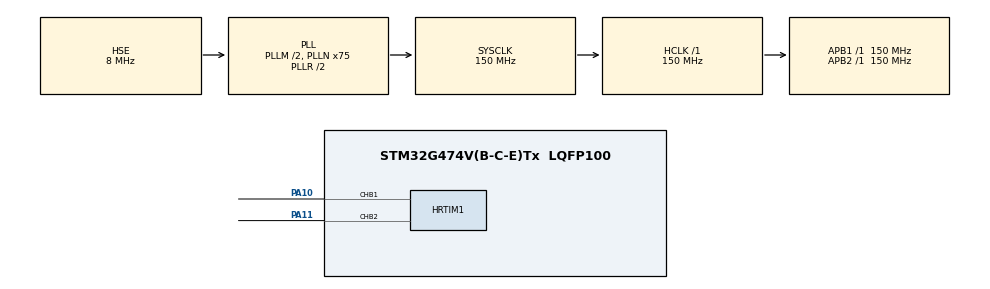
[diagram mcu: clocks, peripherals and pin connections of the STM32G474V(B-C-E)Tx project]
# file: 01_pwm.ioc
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HRTIM1.CompareUnit1-Output_TB1TB2=HRTIM_COMPAREUNIT_1
HRTIM1.CompareValue1-Output_TB1TB2=0
HRTIM1.DeadTimeInsertion-Output_TB1TB2=HRTIM_TIMDEADTIMEINSERTION_ENABLED
HRTIM1.FallingValue-Output_TB1TB2=200
HRTIM1.NumberResetSource1-Output_TB1TB2=1
HRTIM1.NumberSetSource1-Output_TB1TB2=1
HRTIM1.Periode_TB=30000
HRTIM1.PreloadEnable-Output_TB1TB2=HRTIM_PRELOAD_ENABLED
HRTIM1.PrescalerDead-Output_TB1TB2=HRTIM_TIMDEADTIME_PRESCALERRATIO_DIV1
HRTIM1.PrescalerRatio_TB=HRTIM_PRESCALERRATIO_MUL4
HRTIM1.RepetitionUpdate-Output_TB1TB2=HRTIM_UPDATEONREPETITION_ENABLED
HRTIM1.ResetOutput1_Source1-Output_TB1TB2=HRTIM_OUTPUTRESET_TIMCMP1
HRTIM1.RisingValue-Output_TB1TB2=200
HRTIM1.SetOutput1_Source1-Output_TB1TB2=HRTIM_OUTPUTSET_TIMPER
Mcu.Family=STM32G4
Mcu.Name=STM32G474V(B-C-E)Tx
Mcu.Package=LQFP100
NVIC.PriorityGroup=NVIC_PRIORITYGROUP_4
PA10.Mode=Output_TB1TB2
PA10.Signal=HRTIM1_CHB1
PA11.Mode=Output_TB1TB2
PA11.Signal=HRTIM1_CHB2
PA13.Mode=Serial_Wire
PA13.Signal=SYS_JTMS-SWDIO
PA14.Mode=Serial_Wire
PA14.Signal=SYS_JTCK-SWCLK
PC14-OSC32_IN.Mode=LSE-External-Oscillator
PC14-OSC32_IN.Signal=RCC_OSC32_IN
PC15-OSC32_OUT.Mode=LSE-External-Oscillator
PC15-OSC32_OUT.Signal=RCC_OSC32_OUT
PF0-OSC_IN.Mode=HSE-External-Oscillator
PF0-OSC_IN.Signal=RCC_OSC_IN
PF1-OSC_OUT.Mode=HSE-External-Oscillator
PF1-OSC_OUT.Signal=RCC_OSC_OUT
ProjectManager.HeapSize=0x200
ProjectManager.StackSize=0x400
ProjectManager.TargetToolchain=MDK-ARM V5.32
RCC.ADC12Freq_Value=150000000
RCC.ADC345Freq_Value=150000000
RCC.AHBFreq_Value=150000000
RCC.APB1Freq_Value=150000000
RCC.APB1TimFreq_Value=150000000
RCC.APB2Freq_Value=150000000
RCC.APB2TimFreq_Value=150000000
RCC.CortexFreq_Value=150000000
RCC.EXTERNAL_CLOCK_VALUE=12288000
RCC.HCLKFreq_Value=150000000
RCC.HSE_VALUE=8000000
RCC.HSI48_VALUE=48000000
RCC.HSI_VALUE=16000000
RCC.PLLM=RCC_PLLM_DIV2
RCC.PLLN=75
RCC.PLLSourceVirtual=RCC_PLLSOURCE_HSE
RCC.SYSCLKFreq_VALUE=150000000
RCC.SYSCLKSource=RCC_SYSCLKSOURCE_PLLCLK
RCC.USBFreq_Value=150000000
RCC.VCOOutputFreq_Value=300000000
VP_SYS_VS_DBSignals.Mode=DisableDeadBatterySignals
board=custom

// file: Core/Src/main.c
/* USER CODE BEGIN Header */
/**
  ******************************************************************************
  * @file           : main.c
  * @brief          : Main program body
  ******************************************************************************
  * @attention
  *
  * Copyright (c) 2026 STMicroelectronics.
  * All rights reserved.
  *
  * This software is licensed under terms that can be found in the LICENSE file
  * in the root directory of this software component.
  * If no LICENSE file comes with this software, it is provided AS-IS.
  *
  ******************************************************************************
  */
/* USER CODE END Header */
#include "main.h"
#include "hrtim.h"
#include "gpio.h"

void SystemClock_Config(void);

int main(void)
{

  /* MCU Configuration--------------------------------------------------------*/

  /* Reset of all peripherals, Initializes the Flash interface and the Systick. */
  HAL_Init();

  /* Configure the system clock */
  SystemClock_Config();

  /* Initialize all configured peripherals */
  MX_GPIO_Init();
  MX_HRTIM1_Init();

  /* Infinite loop */
  /* USER CODE BEGIN WHILE */

	HAL_HRTIM_WaveformCounterStart(&hhrtim1,HRTIM_TIMERID_TIMER_B);//开定时器
	HAL_HRTIM_WaveformOutputStart(&hhrtim1,HRTIM_OUTPUT_TB1|HRTIM_OUTPUT_TB2);//开通道
	HRTIM1->sTimerxRegs[HRTIM_TIMERINDEX_TIMER_B].CMP1CxR = 15000;//改占空比
  while (1)
  {
    /* USER CODE END WHILE */

  }
}

void SystemClock_Config(void)
{
  RCC_OscInitTypeDef RCC_OscInitStruct = {0};
  RCC_ClkInitTypeDef RCC_ClkInitStruct = {0};

  /** Configure the main internal regulator output voltage
  */
  HAL_PWREx_ControlVoltageScaling(PWR_REGULATOR_VOLTAGE_SCALE1);

  /** Initializes the RCC Oscillators according to the specified parameters
  * in the RCC_OscInitTypeDef structure.
  */
  RCC_OscInitStruct.OscillatorType = RCC_OSCILLATORTYPE_HSE;
  RCC_OscInitStruct.HSEState = RCC_HSE_ON;
  RCC_OscInitStruct.PLL.PLLState = RCC_PLL_ON;
  RCC_OscInitStruct.PLL.PLLSource = RCC_PLLSOURCE_HSE;
  RCC_OscInitStruct.PLL.PLLM = RCC_PLLM_DIV2;
  RCC_OscInitStruct.PLL.PLLN = 75;
  RCC_OscInitStruct.PLL.PLLP = RCC_PLLP_DIV2;
  RCC_OscInitStruct.PLL.PLLQ = RCC_PLLQ_DIV2;
  RCC_OscInitStruct.PLL.PLLR = RCC_PLLR_DIV2;
  if (HAL_RCC_OscConfig(&RCC_OscInitStruct) != HAL_OK)
  {
    Error_Handler();
  }

  /** Initializes the CPU, AHB and APB buses clocks
  */
  RCC_ClkInitStruct.ClockType = RCC_CLOCKTYPE_HCLK|RCC_CLOCKTYPE_SYSCLK
                              |RCC_CLOCKTYPE_PCLK1|RCC_CLOCKTYPE_PCLK2;
  RCC_ClkInitStruct.SYSCLKSource = RCC_SYSCLKSOURCE_PLLCLK;
  RCC_ClkInitStruct.AHBCLKDivider = RCC_SYSCLK_DIV1;
  RCC_ClkInitStruct.APB1CLKDivider = RCC_HCLK_DIV1;
  RCC_ClkInitStruct.APB2CLKDivider = RCC_HCLK_DIV1;

  if (HAL_RCC_ClockConfig(&RCC_ClkInitStruct, FLASH_LATENCY_4) != HAL_OK)
  {
    Error_Handler();
  }
}

void Error_Handler(void)
{
  __disable_irq();
  while (1)
  {
  }
}
